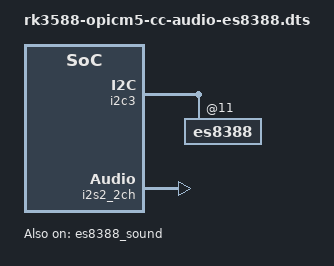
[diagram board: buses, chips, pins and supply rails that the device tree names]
/dts-v1/;
/plugin/;

/ {
	fragment@0 {
		target = <&es8388_sound>;
		__overlay__ {
			status = "okay";
		};
	};

	fragment@1 {
		target = <&i2c3>;
		__overlay__ {
			status = "okay";

			es8388@11 {
				status = "okay";
			};
		};
	};

	fragment@2 {
		target = <&i2s2_2ch>;
		__overlay__ {
			status = "okay";
		};
	};
};
